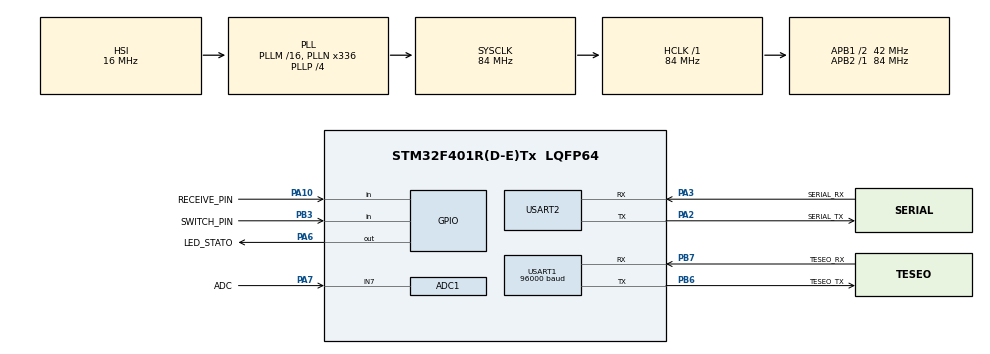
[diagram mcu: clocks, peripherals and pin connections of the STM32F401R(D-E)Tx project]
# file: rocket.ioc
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ADC1.Channel-9\#ChannelRegularConversion=ADC_CHANNEL_7
ADC1.NbrOfConversionFlag=1
ADC1.Rank-9\#ChannelRegularConversion=1
ADC1.SamplingTime-9\#ChannelRegularConversion=ADC_SAMPLETIME_3CYCLES
ADC1.master=1
Mcu.Family=STM32F4
Mcu.Name=STM32F401R(D-E)Tx
Mcu.Package=LQFP64
NVIC.PriorityGroup=NVIC_PRIORITYGROUP_4
PA10.GPIO_Label=RECEIVE_PIN
PA10.Signal=GPIO_Input
PA2.GPIO_Label=SERIAL_TX
PA2.Mode=Asynchronous
PA2.Signal=USART2_TX
PA3.GPIO_Label=SERIAL_RX
PA3.Mode=Asynchronous
PA3.Signal=USART2_RX
PA6.GPIO_Label=LED_STATO
PA6.Signal=GPIO_Output
PA7.GPIO_Label=ADC
PA7.Signal=ADCx_IN7
PB3.GPIO_Label=SWITCH_PIN
PB3.GPIO_PuPd=GPIO_PULLUP
PB3.Signal=GPIO_Input
PB6.GPIO_Label=TESEO_TX
PB6.Mode=Asynchronous
PB6.Signal=USART1_TX
PB7.GPIO_Label=TESEO_RX
PB7.Mode=Asynchronous
PB7.Signal=USART1_RX
ProjectManager.HeapSize=0x200
ProjectManager.StackSize=0x400
ProjectManager.TargetToolchain=STM32CubeIDE
RCC.48MHZClocksFreq_Value=48000000
RCC.AHBFreq_Value=84000000
RCC.APB1CLKDivider=RCC_HCLK_DIV2
RCC.APB1Freq_Value=42000000
RCC.APB1TimFreq_Value=84000000
RCC.APB2Freq_Value=84000000
RCC.APB2TimFreq_Value=84000000
RCC.CortexFreq_Value=84000000
RCC.HCLKFreq_Value=84000000
RCC.HSE_VALUE=8000000
RCC.HSI_VALUE=16000000
RCC.LSE_VALUE=32768
RCC.PLLN=336
RCC.PLLP=RCC_PLLP_DIV4
RCC.PLLQ=7
RCC.SYSCLKFreq_VALUE=84000000
RCC.SYSCLKSource=RCC_SYSCLKSOURCE_PLLCLK
RCC.VCOOutputFreq_Value=336000000
SH.ADCx_IN7.0=ADC1_IN7,IN7
USART1.BaudRate=96000
USART1.VirtualMode=VM_ASYNC
USART2.VirtualMode=VM_ASYNC
board=NUCLEO-F401RE

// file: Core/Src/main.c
/* USER CODE BEGIN Header */
/**
  ******************************************************************************
  * @file           : main.c
  * @brief          : Main program body
  ******************************************************************************
  * @attention
  *
  * Copyright (c) 2026 STMicroelectronics.
  * All rights reserved.
  *
  * This software is licensed under terms that can be found in the LICENSE file
  * in the root directory of this software component.
  * If no LICENSE file comes with this software, it is provided AS-IS.
  *
  ******************************************************************************
  */
/* USER CODE END Header */
#include "main.h"

/* USER CODE BEGIN Includes */
#include <stdio.h>
#include <string.h>

/* USER CODE END Includes */

ADC_HandleTypeDef hadc1;

UART_HandleTypeDef huart1;
UART_HandleTypeDef huart2;

/* USER CODE BEGIN PV */
enum stato_label {WAIT, RECEIVE,NAN};

int stato=WAIT;
int stato_precedente = NAN;

uint32_t adc_value = 0;
float voltaggio_letto= 0.0f;
float voltaggio_reale= 0.0f;

/* USER CODE END PV */

void SystemClock_Config(void);
static void MX_GPIO_Init(void);
static void MX_ADC1_Init(void);
static void MX_USART2_UART_Init(void);
static void MX_USART1_UART_Init(void);

#ifdef __GNUC__
  #define PUTCHAR_PROTOTYPE int __io_putchar(int ch)
#else
  #define PUTCHAR_PROTOTYPE int fputc(int ch, FILE *f)
#endif

PUTCHAR_PROTOTYPE
{
  HAL_UART_Transmit(&huart2, (uint8_t *)&ch, 1, 0xFFFF);
  return ch;
}

int main(void)
{

  /* MCU Configuration--------------------------------------------------------*/

  /* Reset of all peripherals, Initializes the Flash interface and the Systick. */
  HAL_Init();

  /* Configure the system clock */
  SystemClock_Config();

  /* Initialize all configured peripherals */
  MX_GPIO_Init();
  MX_ADC1_Init();
  MX_USART2_UART_Init();
  MX_USART1_UART_Init();

  /* Infinite loop */
  /* USER CODE BEGIN WHILE */
  while (1)
  {

	HAL_ADC_Start(&hadc1);
	if (HAL_ADC_PollForConversion(&hadc1, 10) == HAL_OK){

	    adc_value = HAL_ADC_GetValue(&hadc1);
	    voltaggio_letto = ((float)adc_value * 3.3f) / 4095.0f;
	    voltaggio_reale= 5* voltaggio_letto;  // Usando come Partitore di tensione due resistori da (10 e 40 kOhm)
	}

	HAL_ADC_Stop(&hadc1);

	 //Switch
	if (HAL_GPIO_ReadPin(GPIOB, GPIO_PIN_3 ) == GPIO_PIN_RESET) {
	        stato = RECEIVE;
	 } else{
	        stato = WAIT;
	 }

	//Risveglio TESEO
	if (stato != stato_precedente) {
	        if (stato == WAIT) {
	            // Manda il Teseo in Standby via UART1
	            char *stop_cmd = "$PSTMSTBY\r\n";
	            HAL_UART_Transmit(&huart1, (uint8_t*)stop_cmd, strlen(stop_cmd), 100);
	            printf("\r\n[MODE: WAIT] GPS in Standby.\r\n");
	        }
	        else {
	            // Risveglia il Teseo
	            char *wake_cmd = "WAKEUP\r\n";
	            HAL_UART_Transmit(&huart1, (uint8_t*)wake_cmd, strlen(wake_cmd), 100);
	            printf("\r\n[MODE: RECEIVE] GPS Attivato.\r\n");
	        }
	        stato_precedente = stato;
	    }

	//Led + GPS + STAMPA
    if(stato ==RECEIVE){
      HAL_GPIO_TogglePin(GPIOA, GPIO_PIN_6); //Lampeggia LED
      uint8_t gps_buffer[120]={0};

          // Ricezione dati NMEA dal Teseo (USART1)
      	  if (HAL_UART_Receive(&huart1, gps_buffer, 120, 500) == HAL_OK) {
                  printf("V: %.2fV | GPS: %s\r\n", voltaggio_reale, gps_buffer);
      	  } else {
                  printf("V: %.2fV | GPS: In attesa dati...\r\n", voltaggio_reale);
              }

     }else {
              // --- MODALITA' WAIT ---
              HAL_GPIO_WritePin(GPIOA, GPIO_PIN_6, GPIO_PIN_SET); // LED Fisso
              printf("V Reali: %.2fV (Sistema in attesa)\r\n", voltaggio_reale);
              HAL_Delay(200);

          }

  }
  /* USER CODE END 3 */
}

void SystemClock_Config(void)
{
  RCC_OscInitTypeDef RCC_OscInitStruct = {0};
  RCC_ClkInitTypeDef RCC_ClkInitStruct = {0};

  /** Configure the main internal regulator output voltage
  */
  __HAL_RCC_PWR_CLK_ENABLE();
  __HAL_PWR_VOLTAGESCALING_CONFIG(PWR_REGULATOR_VOLTAGE_SCALE2);

  /** Initializes the RCC Oscillators according to the specified parameters
  * in the RCC_OscInitTypeDef structure.
  */
  RCC_OscInitStruct.OscillatorType = RCC_OSCILLATORTYPE_HSI;
  RCC_OscInitStruct.HSIState = RCC_HSI_ON;
  RCC_OscInitStruct.HSICalibrationValue = RCC_HSICALIBRATION_DEFAULT;
  RCC_OscInitStruct.PLL.PLLState = RCC_PLL_ON;
  RCC_OscInitStruct.PLL.PLLSource = RCC_PLLSOURCE_HSI;
  RCC_OscInitStruct.PLL.PLLM = 16;
  RCC_OscInitStruct.PLL.PLLN = 336;
  RCC_OscInitStruct.PLL.PLLP = RCC_PLLP_DIV4;
  RCC_OscInitStruct.PLL.PLLQ = 7;
  if (HAL_RCC_OscConfig(&RCC_OscInitStruct) != HAL_OK)
  {
    Error_Handler();
  }

  /** Initializes the CPU, AHB and APB buses clocks
  */
  RCC_ClkInitStruct.ClockType = RCC_CLOCKTYPE_HCLK|RCC_CLOCKTYPE_SYSCLK
                              |RCC_CLOCKTYPE_PCLK1|RCC_CLOCKTYPE_PCLK2;
  RCC_ClkInitStruct.SYSCLKSource = RCC_SYSCLKSOURCE_PLLCLK;
  RCC_ClkInitStruct.AHBCLKDivider = RCC_SYSCLK_DIV1;
  RCC_ClkInitStruct.APB1CLKDivider = RCC_HCLK_DIV2;
  RCC_ClkInitStruct.APB2CLKDivider = RCC_HCLK_DIV1;

  if (HAL_RCC_ClockConfig(&RCC_ClkInitStruct, FLASH_LATENCY_2) != HAL_OK)
  {
    Error_Handler();
  }
}

static void MX_ADC1_Init(void)
{

  ADC_ChannelConfTypeDef sConfig = {0};

  /** Configure the global features of the ADC (Clock, Resolution, Data Alignment and number of conversion)
  */
  hadc1.Instance = ADC1;
  hadc1.Init.ClockPrescaler = ADC_CLOCK_SYNC_PCLK_DIV4;
  hadc1.Init.Resolution = ADC_RESOLUTION_12B;
  hadc1.Init.ScanConvMode = DISABLE;
  hadc1.Init.ContinuousConvMode = DISABLE;
  hadc1.Init.DiscontinuousConvMode = DISABLE;
  hadc1.Init.ExternalTrigConvEdge = ADC_EXTERNALTRIGCONVEDGE_NONE;
  hadc1.Init.ExternalTrigConv = ADC_SOFTWARE_START;
  hadc1.Init.DataAlign = ADC_DATAALIGN_RIGHT;
  hadc1.Init.NbrOfConversion = 1;
  hadc1.Init.DMAContinuousRequests = DISABLE;
  hadc1.Init.EOCSelection = ADC_EOC_SINGLE_CONV;
  if (HAL_ADC_Init(&hadc1) != HAL_OK)
  {
    Error_Handler();
  }

  /** Configure for the selected ADC regular channel its corresponding rank in the sequencer and its sample time.
  */
  sConfig.Channel = ADC_CHANNEL_7;
  sConfig.Rank = 1;
  sConfig.SamplingTime = ADC_SAMPLETIME_3CYCLES;
  if (HAL_ADC_ConfigChannel(&hadc1, &sConfig) != HAL_OK)
  {
    Error_Handler();
  }

}

static void MX_USART1_UART_Init(void)
{

  huart1.Instance = USART1;
  huart1.Init.BaudRate = 96000;
  huart1.Init.WordLength = UART_WORDLENGTH_8B;
  huart1.Init.StopBits = UART_STOPBITS_1;
  huart1.Init.Parity = UART_PARITY_NONE;
  huart1.Init.Mode = UART_MODE_TX_RX;
  huart1.Init.HwFlowCtl = UART_HWCONTROL_NONE;
  huart1.Init.OverSampling = UART_OVERSAMPLING_16;
  if (HAL_UART_Init(&huart1) != HAL_OK)
  {
    Error_Handler();
  }

}

static void MX_USART2_UART_Init(void)
{

  huart2.Instance = USART2;
  huart2.Init.BaudRate = 115200;
  huart2.Init.WordLength = UART_WORDLENGTH_8B;
  huart2.Init.StopBits = UART_STOPBITS_1;
  huart2.Init.Parity = UART_PARITY_NONE;
  huart2.Init.Mode = UART_MODE_TX_RX;
  huart2.Init.HwFlowCtl = UART_HWCONTROL_NONE;
  huart2.Init.OverSampling = UART_OVERSAMPLING_16;
  if (HAL_UART_Init(&huart2) != HAL_OK)
  {
    Error_Handler();
  }

}

static void MX_GPIO_Init(void)
{
  GPIO_InitTypeDef GPIO_InitStruct = {0};

  /* GPIO Ports Clock Enable */
  __HAL_RCC_GPIOA_CLK_ENABLE();
  __HAL_RCC_GPIOB_CLK_ENABLE();

  /*Configure GPIO pin Output Level */
  HAL_GPIO_WritePin(LED_STATO_GPIO_Port, LED_STATO_Pin, GPIO_PIN_RESET);

  /*Configure GPIO pin : LED_STATO_Pin */
  GPIO_InitStruct.Pin = LED_STATO_Pin;
  GPIO_InitStruct.Mode = GPIO_MODE_OUTPUT_PP;
  GPIO_InitStruct.Pull = GPIO_NOPULL;
  GPIO_InitStruct.Speed = GPIO_SPEED_FREQ_LOW;
  HAL_GPIO_Init(LED_STATO_GPIO_Port, &GPIO_InitStruct);

  /*Configure GPIO pin : RECEIVE_PIN_Pin */
  GPIO_InitStruct.Pin = RECEIVE_PIN_Pin;
  GPIO_InitStruct.Mode = GPIO_MODE_INPUT;
  GPIO_InitStruct.Pull = GPIO_NOPULL;
  HAL_GPIO_Init(RECEIVE_PIN_GPIO_Port, &GPIO_InitStruct);

  /*Configure GPIO pin : SWITCH_PIN_Pin */
  GPIO_InitStruct.Pin = SWITCH_PIN_Pin;
  GPIO_InitStruct.Mode = GPIO_MODE_INPUT;
  GPIO_InitStruct.Pull = GPIO_PULLUP;
  HAL_GPIO_Init(SWITCH_PIN_GPIO_Port, &GPIO_InitStruct);

}

void Error_Handler(void)
{
  __disable_irq();
  while (1)
  {
  }
}
